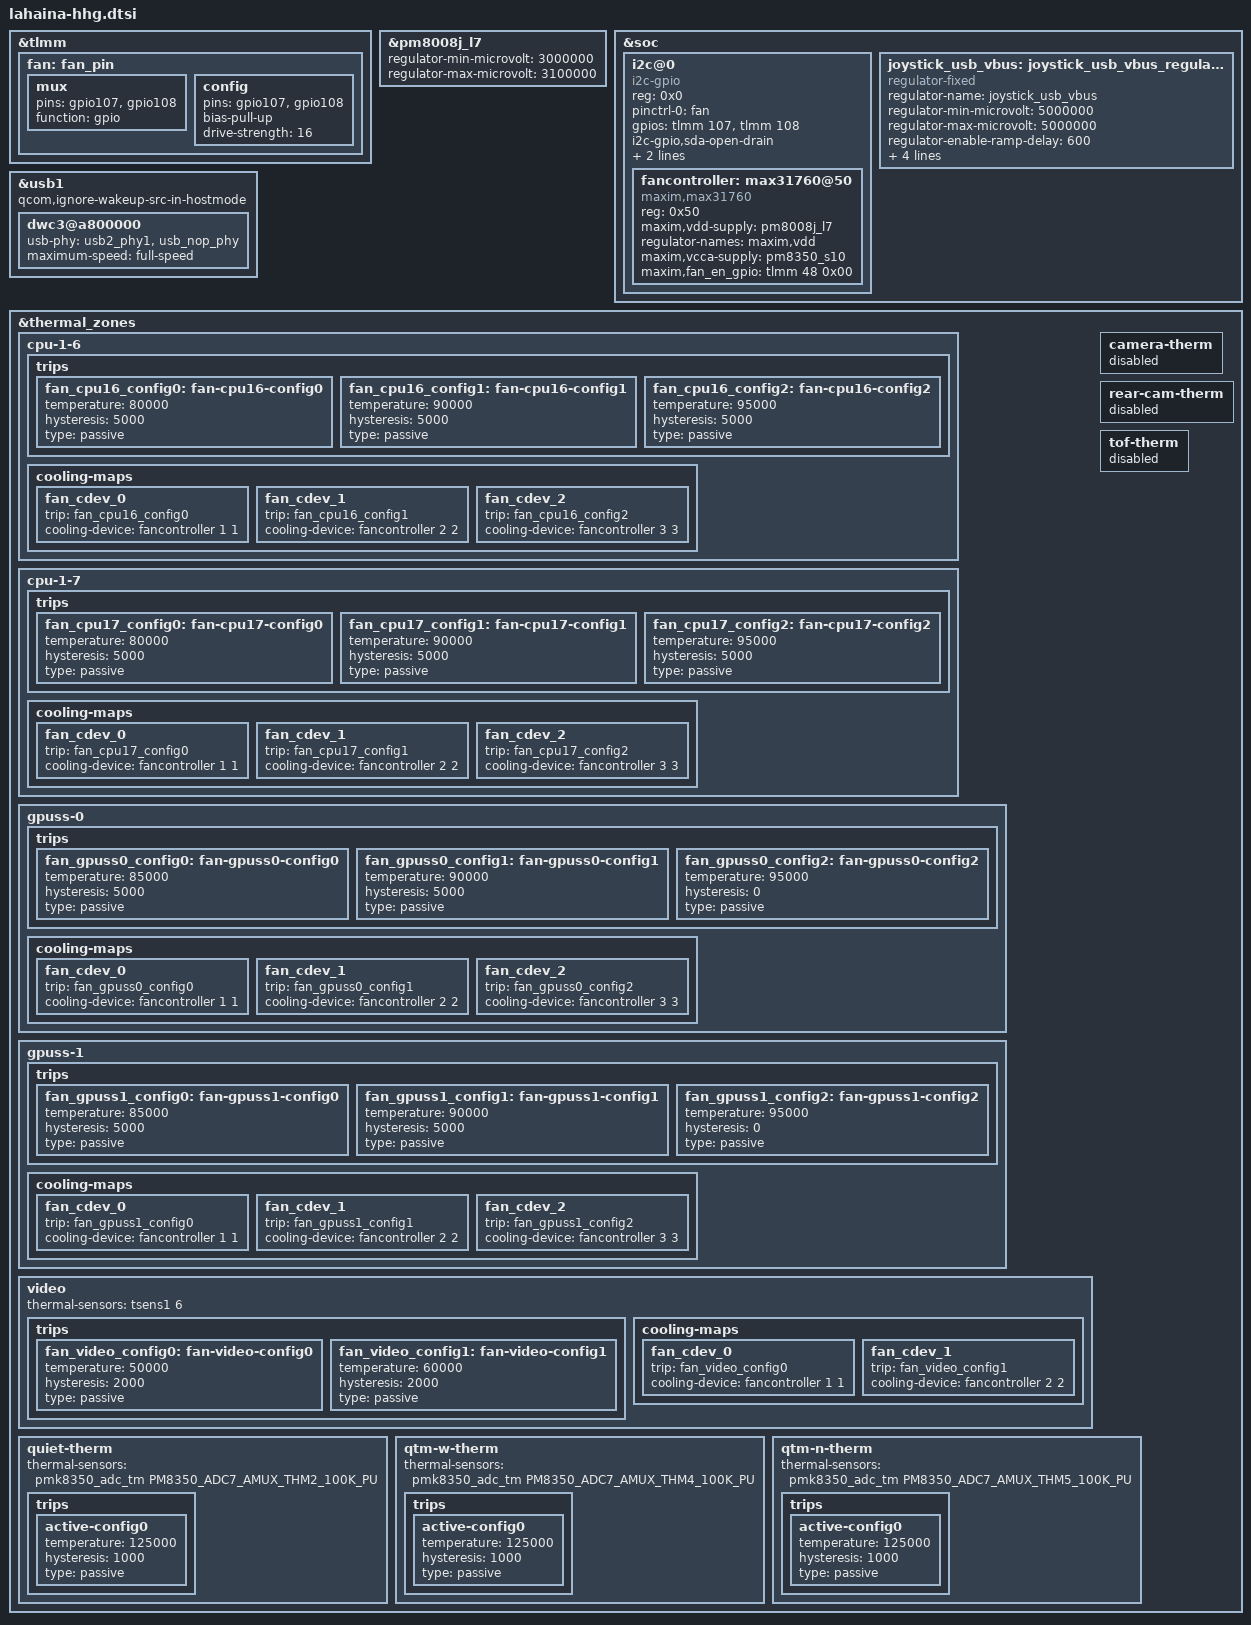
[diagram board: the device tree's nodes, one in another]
// SPDX-License-Identifier: BSD-3-Clause
/*
 * Copyright (c) Qualcomm Technologies, Inc. and/or its subsidiaries.
 */

#include "lahaina-hdk.dtsi"

&tlmm {
	fan: fan_pin {
		mux {
			pins = "gpio107","gpio108";
			function = "gpio";
		};

		config {
			pins = "gpio107","gpio108";
			bias-pull-up;
			drive-strength = <16>;
		};
	};
};

&pm8008j_l7 {
	regulator-min-microvolt = <3000000>;
	regulator-max-microvolt = <3100000>;
};

&soc {
	i2c@0 {
		compatible = "i2c-gpio";
		reg = <0x0>;
		pinctrl-names = "default";
		pinctrl-0 = <&fan>;
		gpios = <&tlmm 107 (GPIO_ACTIVE_HIGH | GPIO_OPEN_DRAIN) /* sda */>,
			<&tlmm 108 (GPIO_ACTIVE_HIGH | GPIO_OPEN_DRAIN) /* scl */>;

		i2c-gpio,sda-open-drain;
		i2c-gpio,scl-open-drain;
		i2c-gpio,delay-us = <5>;
		#address-cells = <1>;
		#size-cells = <0>;

		fancontroller: max31760@50 {
			compatible = "maxim,max31760";
			reg = <0x50>;
			#cooling-cells = <2>;
			maxim,vdd-supply = <&pm8008j_l7>;
			regulator-names = "maxim,vdd";
			maxim,vcca-supply = <&pm8350_s10>;
			maxim,fan_en_gpio = <&tlmm 48 0x00>;
			status = "ok";
		};
	};

	joystick_usb_vbus: joystick_usb_vbus_regulator {
		compatible = "regulator-fixed";
		regulator-name = "joystick_usb_vbus";
		regulator-min-microvolt = <5000000>;
		regulator-max-microvolt = <5000000>;
		regulator-enable-ramp-delay = <600>;
		gpio = <&pm8350_gpios 8 GPIO_ACTIVE_HIGH>;
		enable-active-high;
		regulator-always-on;
		pinctrl-names = "default";
		pinctrl-0 = <&usb2_vbus_boost_default>;
	};
};

&usb1 {
	qcom,ignore-wakeup-src-in-hostmode;

	dwc3@a800000 {
		usb-phy = <&usb2_phy1>, <&usb_nop_phy>;
		maximum-speed = "full-speed";
	};
};

&thermal_zones {
	cpu-1-6 {
		trips {
			fan_cpu16_config0: fan-cpu16-config0 {
				temperature = <80000>;
				hysteresis = <5000>;
				type = "passive";
			};

			fan_cpu16_config1: fan-cpu16-config1 {
				temperature = <90000>;
				hysteresis = <5000>;
				type = "passive";
			};

			fan_cpu16_config2: fan-cpu16-config2 {
				temperature = <95000>;
				hysteresis = <5000>;
				type = "passive";
			};
		};

		cooling-maps {
			fan_cdev_0 {
				trip = <&fan_cpu16_config0>;
				cooling-device = <&fancontroller 1 1>;
			};

			fan_cdev_1 {
				trip = <&fan_cpu16_config1>;
				cooling-device = <&fancontroller 2 2>;
			};

			fan_cdev_2 {
				trip = <&fan_cpu16_config2>;
				cooling-device = <&fancontroller 3 3>;
			};
		};
	};

	cpu-1-7 {
		trips {
			fan_cpu17_config0: fan-cpu17-config0 {
				temperature = <80000>;
				hysteresis = <5000>;
				type = "passive";
			};

			fan_cpu17_config1: fan-cpu17-config1 {
				temperature = <90000>;
				hysteresis = <5000>;
				type = "passive";
			};

			fan_cpu17_config2: fan-cpu17-config2 {
				temperature = <95000>;
				hysteresis = <5000>;
				type = "passive";
			};
		};

		cooling-maps {
			fan_cdev_0 {
				trip = <&fan_cpu17_config0>;
				cooling-device = <&fancontroller 1 1>;
			};

			fan_cdev_1 {
				trip = <&fan_cpu17_config1>;
				cooling-device = <&fancontroller 2 2>;
			};

			fan_cdev_2 {
				trip = <&fan_cpu17_config2>;
				cooling-device = <&fancontroller 3 3>;
			};
		};
	};

	gpuss-0 {
		trips {
			fan_gpuss0_config0: fan-gpuss0-config0 {
				temperature = <85000>;
				hysteresis = <5000>;
				type = "passive";
			};

			fan_gpuss0_config1: fan-gpuss0-config1 {
				temperature = <90000>;
				hysteresis = <5000>;
				type = "passive";
			};

			fan_gpuss0_config2: fan-gpuss0-config2 {
				temperature = <95000>;
				hysteresis = <0>;
				type = "passive";
			};
		};

		cooling-maps {
			fan_cdev_0 {
				trip = <&fan_gpuss0_config0>;
				cooling-device = <&fancontroller 1 1>;
			};

			fan_cdev_1 {
				trip = <&fan_gpuss0_config1>;
				cooling-device = <&fancontroller 2 2>;
			};

			fan_cdev_2 {
				trip = <&fan_gpuss0_config2>;
				cooling-device = <&fancontroller 3 3>;
			};
		};
	};

	gpuss-1 {
		trips {
			fan_gpuss1_config0: fan-gpuss1-config0 {
				temperature = <85000>;
				hysteresis = <5000>;
				type = "passive";
			};

			fan_gpuss1_config1: fan-gpuss1-config1 {
				temperature = <90000>;
				hysteresis = <5000>;
				type = "passive";
			};

			fan_gpuss1_config2: fan-gpuss1-config2 {
				temperature = <95000>;
				hysteresis = <0>;
				type = "passive";
			};
		};

		cooling-maps {
			fan_cdev_0 {
				trip = <&fan_gpuss1_config0>;
				cooling-device = <&fancontroller 1 1>;
			};

			fan_cdev_1 {
				trip = <&fan_gpuss1_config1>;
				cooling-device = <&fancontroller 2 2>;
			};

			fan_cdev_2 {
				trip = <&fan_gpuss1_config2>;
				cooling-device = <&fancontroller 3 3>;
			};
		};
	};

	video {
		thermal-sensors = <&tsens1 6>;
		trips {
			fan_video_config0: fan-video-config0 {
				temperature = <50000>;
				hysteresis = <2000>;
				type = "passive";
			};

			fan_video_config1: fan-video-config1 {
				temperature = <60000>;
				hysteresis = <2000>;
				type = "passive";
			};
		};

		cooling-maps {
			fan_cdev_0 {
				trip = <&fan_video_config0>;
				cooling-device = <&fancontroller 1 1>;
			};

			fan_cdev_1 {
				trip = <&fan_video_config1>;
				cooling-device = <&fancontroller 2 2>;
			};
		};
	};

	camera-therm {
		status = "disabled";
	};

	rear-cam-therm {
		status = "disabled";
	};

	tof-therm {
		status = "disabled";
	};

	quiet-therm {
		thermal-sensors = <&pmk8350_adc_tm PM8350_ADC7_AMUX_THM2_100K_PU>;
		trips {
			active-config0 {
				temperature = <125000>;
				hysteresis = <1000>;
				type = "passive";
			};
		};
	};

	qtm-w-therm {
		thermal-sensors = <&pmk8350_adc_tm PM8350_ADC7_AMUX_THM4_100K_PU>;
		trips {
			active-config0 {
				temperature = <125000>;
				hysteresis = <1000>;
				type = "passive";
			};
		};
	};

	qtm-n-therm {
		thermal-sensors = <&pmk8350_adc_tm PM8350_ADC7_AMUX_THM5_100K_PU>;
		trips {
			active-config0 {
				temperature = <125000>;
				hysteresis = <1000>;
				type = "passive";
			};
		};
	};
};
